# SMARTREFLEX_MPU register map
Vendor: Texas Instruments
Peripheral module from a debugger description file (folder omap5430_ES2_PUBLIC).
Registers are 32-bit, read-only, reset 0x0 unless marked. A register's access mark holds for its fields unless they carry their own. Offsets are as the file gives them; lines under a group give offsets from that group; [hi:lo] are bit positions; {n}, {i} and the like mark numbered series; 'fields as' and 'values as' point back to an identical list; <NAME> marks a mode.

## SMARTREFLEX_MPU
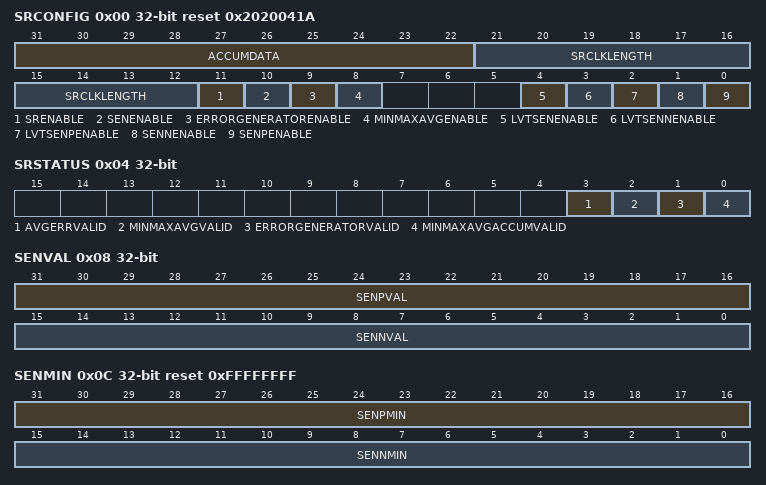
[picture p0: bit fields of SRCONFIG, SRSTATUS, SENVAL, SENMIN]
0x00 SRCONFIG rw reset 0x2020041A — Configuration bits for the Sensor Core and the Digital Processing.
  [31:22] ACCUMDATA — Number of Values to Accumulate
  [21:12] SRCLKLENGTH — Determines frequency of SMARTREFLEX_CLK
  [11] SRENABLE — 0: Synchronously resets MINMAXAVGACCUMVALID, MINMAXAVGVALID, ERRORGENERATORVALID, ACCUMDATA sensor, SMARTREFLEX_CLK counter, and MINMAXAVG bits. Also gates the clock for power savings and disables all the digital logic. 1: Enables the module
  [10] SENENABLE — 0: All SVT sensors disabled 1: SVT sensors enabled per SenNEnable and SenPEnable
  [9] ERRORGENERATORENABLE — 0: Error Generator Module disabled 1: Error Generator Module enabled
  [8] MINMAXAVGENABLE — 0: Min/Max/Avg Detector Module disabled 1: Min/Max/Avg Detector Module enabled
  [4] LVTSENENABLE — LVT sensor enable control 0x0: All LVT sensors disabled 0x1: LVT Sensors enabled per LVTSENxENABLE (x=N/P)
  [3] LVTSENNENABLE — LVT SensorN enable control 0x0: Disables LVTSenN sensor 0x1: Enables LVTSenN sensor
  [2] LVTSENPENABLE — LVT SensorP enable control 0x0: Disables LVTSenP sensor 0x1: Enables LVTSenP sensor
  [1] SENNENABLE — 0: Disable SenN sensor 1: Enable SenN sensor
  [0] SENPENABLE — 0: Disable SenP sensor 1: Enable SenP sensor
0x04 SRSTATUS — Status bits that indicate that the values in the register are valid or events have occurred.
  [3] AVGERRVALID — 0: AVGERROR bits are not valid 1: AVGERROR bits are valid.
  [2] MINMAXAVGVALID — 0:SENVAL, SENMIN, SENMAX, SENAVG registers are not valid 1: SeENVAL, SENMIN, SENMAX, SENAVG registers are valid, but not necessarily fully accumulated
  [1] ERRORGENERATORVALID — 0:SENERROR_REG register do not have valid data 1: SENERROR_REG registers have valid data.
  [0] MINMAXAVGACCUMVALID — 0:SENVAL, SENMIN, SENMAX, SENAVG registers are not valid 1: SENVAL, SENMIN, SENMAX, SENAVG registers have valid, final data
0x08 SENVAL — The current sensor values from the Sensor Core (SVT)
  [31:16] SENPVAL — The latest value of the SenPVal from the SVT sensor core.
  [15:0] SENNVAL — The latest value of the SenNVal from the SVT sensor core.
0x0C SENMIN reset 0xFFFFFFFF — The minimum sensor values (SVT)
  [31:16] SENPMIN — The minimum value of the SenPVal from the SVT sensor core since the last restat operation.
  [15:0] SENNMIN — The minimum value of the SenNVal from the SVT sensor core since the last restat operation.
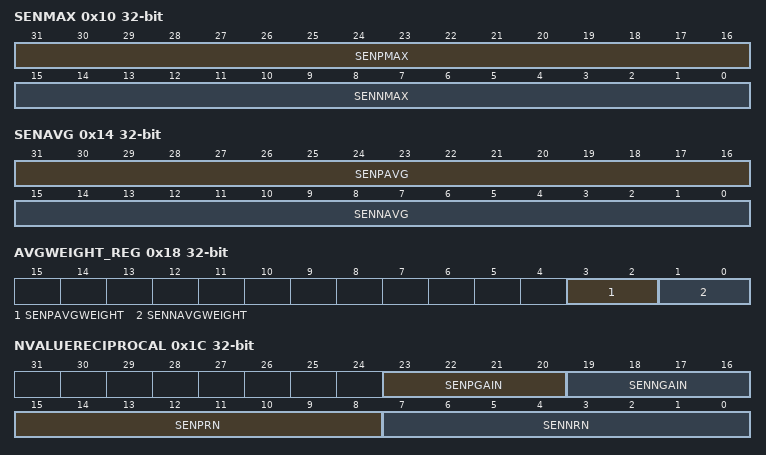
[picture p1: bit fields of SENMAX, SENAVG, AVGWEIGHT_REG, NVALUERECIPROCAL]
0x10 SENMAX — The maximum sensor values (SVT)
  [31:16] SENPMAX — The maximum value of the SenPVal from the SVT sensor core since the last restat operation.
  [15:0] SENNMAX — The maximum value of the SenNVal from the SVT sensor core since the last restat operation.
0x14 SENAVG — The average sensor values (SVT)
  [31:16] SENPAVG — The running average of the SenPVal from the SVT sensor core since the last restat operation.
  [15:0] SENNAVG — The running average of the SenNVal from the SVT sensor core since the last restat operation.
0x18 AVGWEIGHT_REG access per field — The weighting factor in the average computation.
  [3:2] SENPAVGWEIGHT rw — The weighting factor for the SenP averager.
  [1:0] SENNAVGWEIGHT rw — The weighting factor for the SenN averager.
0x1C NVALUERECIPROCAL access per field — The reciprocal of the SenN and SenP values used in error generation (SVT)
  [23:20] SENPGAIN rw — The gain value for the SVT SenP reciprocal.
  [19:16] SENNGAIN rw — The gain value for the SVT SenN reciprocal.
  [15:8] SENPRN rw — The scale value for the SVT SenP reciprocal.
  [7:0] SENNRN rw — The scale value for the SVT SenN reciprocal.
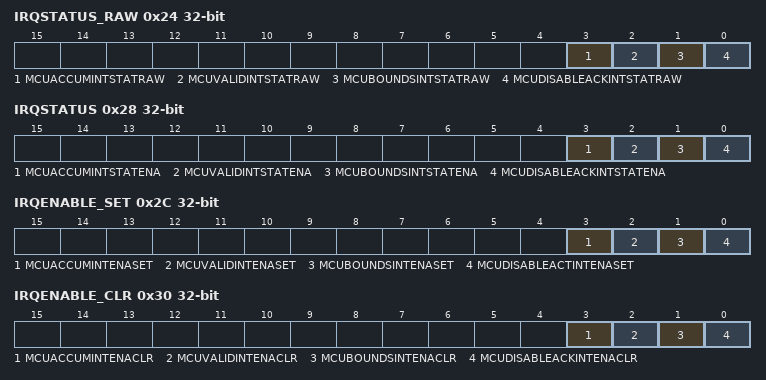
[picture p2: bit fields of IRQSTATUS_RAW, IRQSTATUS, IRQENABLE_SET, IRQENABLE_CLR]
0x24 IRQSTATUS_RAW access per field — MPU raw interrup status and set.
  [3] MCUACCUMINTSTATRAW rw — 0: Accum interrupt status is unchanged 1: Accum interrupt status is set
  [2] MCUVALIDINTSTATRAW rw — 0: Valid interrupt status is unchanged 1: Valid interrupt status is set
  [1] MCUBOUNDSINTSTATRAW rw — 0: Bounds interrupt status is unchanged 1: Bounds interrupt status is set
  [0] MCUDISABLEACKINTSTATRAW rw — 0: MPU Disable acknowledge status is unchanged 1: MPU Disable acknowledge status is set
0x28 IRQSTATUS access per field — MPU masked interrupt status and clear.
  [3] MCUACCUMINTSTATENA rw — Read 0: Accum interrupt status is unchanged Read 1: Accum interrupt status is set Write 0: Accum interrupt status is unchanged Write 1: Accum interrupt status is cleared
  [2] MCUVALIDINTSTATENA rw — Read 0: Valid interrupt status is unchanged Read 1: Valid interrupt status is set Write 0: Valid interrupt status is unchanged Write 1: Valid interrupt status is cleared
  [1] MCUBOUNDSINTSTATENA rw — Read 0: Bounds interrupt status is unchanged Read 1: Bounds interrupt status is set Write 0: Bounds interrupt status is unchanged Write 1: Bounds interrupt status is cleared
  [0] MCUDISABLEACKINTSTATENA rw — Read 0: MPUDisable acknowledge status is unchanged Read 1: MPUDisable acknowledge status is set Write 0: MPUDisable acknowledge status is unchanged Write 1: MPUDisable acknowledge status is cleared
0x2C IRQENABLE_SET access per field — MPU interrupt enable flag and set.
  [3] MCUACCUMINTENASET rw — Read mode: 0: Accum interrupt generation is disabled/masked, 1: Accum interrupt generation is enabled; Write mode: 0: No change to Accum interrupt enable, 1: Enable Accum interrupt generation.
  [2] MCUVALIDINTENASET rw — Read mode: 0: Valid interrupt generation is disabled/masked, 1: Valid interrupt generation is enabled; Write mode: 0: No change to Valid interrupt enable, 1: Enable Valid interrupt generation.
  [1] MCUBOUNDSINTENASET rw — Read mode: 0: Bounds interrupt generation is disabled/masked, 1: Bounds interrupt generation is enabled; Write mode: 0: No change to Bounds interrupt enable, 1: Enable Bounds interrupt generation.
  [0] MCUDISABLEACTINTENASET rw — Read mode: 0: MPUDisableAck interrupt generation is disabled/masked, 1: MPUDisableAck interrupt generation is enabled; Write mode: 0: No change to MPUDisAck interrupt enable, 1: Enable MPUDisableAck interrupt generation.
0x30 IRQENABLE_CLR access per field — MPU interrup enable flag and clear.
  [3] MCUACCUMINTENACLR rw — Read mode: 0: Accum interrupt generation is disabled/masked, 1: Accum interrupt generation is enabled; Write mode: 0: No change to Accum interrupt enable, 1: Disable Accum interrupt generation.
  [2] MCUVALIDINTENACLR rw — Read mode: 0: Valid interrupt generation is disabled/masked, 1: Valid interrupt generation is enabled; Write mode: 0: No change to Valid interrupt enable, 1: Disable Valid interrupt generation.
  [1] MCUBOUNDSINTENACLR rw — Read mode: 0: Bounds interrupt generation is disabled/masked, 1: Bounds interrupt generation is enabled; Write mode: 0: No change to Bounds interrupt enable, 1: Disable Bounds interrupt generation.
  [0] MCUDISABLEACKINTENACLR rw — Read mode: 0: MPUDisableAck interrupt generation is disabled/masked, 1: MPUDisableAck interrupt generation is enabled; Write mode: 0: No change to MPUDisAck interrupt enable, 1: Disable MPUDisableAck interrupt generation.
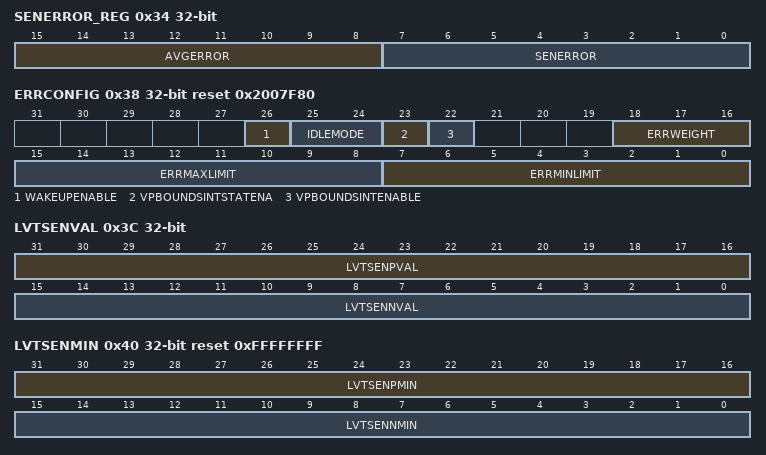
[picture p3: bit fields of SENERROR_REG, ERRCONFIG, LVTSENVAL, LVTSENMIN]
0x34 SENERROR_REG — The sensor error from the error generator.
  [15:8] AVGERROR — The average sensor error.
  [7:0] SENERROR — The percentage of sensor error.
0x38 ERRCONFIG access per field reset 0x2007F80 — The sensor error configuration.
  [26] WAKEUPENABLE rw — Wakeup from MPU Interrupts enable.
  [25:24] IDLEMODE rw — 0b00: Force-Idle Mode, 0b01: No Idle Mode, 0b10: SmartIdle Mode #2, 0b11: Smart-Idle-Wkup mode
  [23] VPBOUNDSINTSTATENA rw — 0: Bounds interrupt status is unchanged, 1: Bounds interrupt status is cleared.
  [22] VPBOUNDSINTENABLE rw — 0: Bounds interrupt disabled, 1: Bounds interrupt enabled.
  [18:16] ERRWEIGHT rw — The AvgSenError weight.
  [15:8] ERRMAXLIMIT rw — The upper limit of SenError for interrupt generation.
  [7:0] ERRMINLIMIT rw — The lower limit of SenError for interrupt generation.
0x3C LVTSENVAL — The current sensor values from the Sensor Core (LVT)
  [31:16] LVTSENPVAL — The latest value of the SenPVal from the LVT sensor core.
  [15:0] LVTSENNVAL — The latest value of the SenNVal from the LVT sensor core.
0x40 LVTSENMIN reset 0xFFFFFFFF — The minimum sensor values (LVT)
  [31:16] LVTSENPMIN — The minimum value of the SenPVal from the LVT sensor core since the last restat operation.
  [15:0] LVTSENNMIN — The minimum value of the SenNVal from the LVT sensor core since the last restat operation.
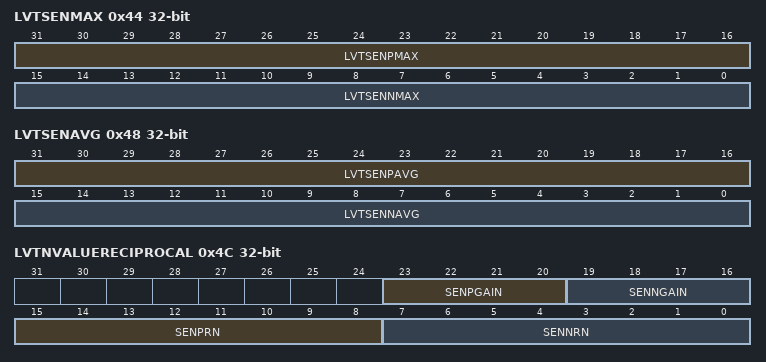
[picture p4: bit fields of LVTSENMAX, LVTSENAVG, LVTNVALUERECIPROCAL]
0x44 LVTSENMAX — The maximum sensor values (LVT)
  [31:16] LVTSENPMAX — The maximum value of the SenPVal from the LVT sensor core since the last restat operation.
  [15:0] LVTSENNMAX — The maximum value of the SenNVal from the LVT sensor core since the last restat operation.
0x48 LVTSENAVG — The average sensor values (LVT)
  [31:16] LVTSENPAVG — The running average of the SenPVal from the LVT sensor core since the last restat operation.
  [15:0] LVTSENNAVG — The running average of the SenNVal from the LVT sensor core since the last restat operation.
0x4C LVTNVALUERECIPROCAL access per field — The reciprocal of the SenN and SenP values used in error generation (LVT)
  [23:20] SENPGAIN rw — The gain value for the LVT SenP reciprocal.
  [19:16] SENNGAIN rw — The gain value for the LVT SenN reciprocal.
  [15:8] SENPRN rw — The scale value for the LVT SenP reciprocal.
  [7:0] SENNRN rw — The scale value for the LVT SenN reciprocal.
